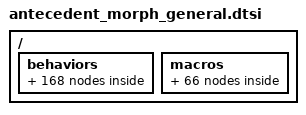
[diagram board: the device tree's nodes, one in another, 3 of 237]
// General schema version v2.9
// Automatically generated by Antecedent Morph Configurator

/ {
    behaviors {
        // Mod-Morphs
        // Base layer
        // NE
        amgnneagm: amgnneagm {
            compatible = "zmk,behavior-mod-morph";
            #binding-cells = <0>;
            bindings = <&amgnnea>, <&amgnneg>;
            mods = <(MOD_LGUI)>;
        };
        amgnnecagm: amgnnecagm {
            compatible = "zmk,behavior-mod-morph";
            #binding-cells = <0>;
            bindings = <&amgnnec>, <&amgnneagm>;
            mods = <(MOD_LALT|MOD_LGUI)>;
        };
        amgnnem: amgnnem {
            compatible = "zmk,behavior-mod-morph";
            #binding-cells = <0>;
            bindings = <&amgnne>, <&amgnnecagm>;
            mods = <(MOD_LCTL|MOD_LALT|MOD_LGUI)>;
        };
        // E
        amgneagm: amgneagm {
            compatible = "zmk,behavior-mod-morph";
            #binding-cells = <0>;
            bindings = <&amgnea>, <&amgneg>;
            mods = <(MOD_LGUI)>;
        };
        amgnecagm: amgnecagm {
            compatible = "zmk,behavior-mod-morph";
            #binding-cells = <0>;
            bindings = <&amgnec>, <&amgneagm>;
            mods = <(MOD_LALT|MOD_LGUI)>;
        };
        amgnem: amgnem {
            compatible = "zmk,behavior-mod-morph";
            #binding-cells = <0>;
            bindings = <&amgne>, <&amgnecagm>;
            mods = <(MOD_LCTL|MOD_LALT|MOD_LGUI)>;
        };
        // SE
        amgnseagm: amgnseagm {
            compatible = "zmk,behavior-mod-morph";
            #binding-cells = <0>;
            bindings = <&amgnsea>, <&amgnseg>;
            mods = <(MOD_LGUI)>;
        };
        amgnsecagm: amgnsecagm {
            compatible = "zmk,behavior-mod-morph";
            #binding-cells = <0>;
            bindings = <&amgnsec>, <&amgnseagm>;
            mods = <(MOD_LALT|MOD_LGUI)>;
        };
        amgnsem: amgnsem {
            compatible = "zmk,behavior-mod-morph";
            #binding-cells = <0>;
            bindings = <&amgnse>, <&amgnsecagm>;
            mods = <(MOD_LCTL|MOD_LALT|MOD_LGUI)>;
        };
        // NW
        amgnnwagm: amgnnwagm {
            compatible = "zmk,behavior-mod-morph";
            #binding-cells = <0>;
            bindings = <&amgnnwa>, <&amgnnwg>;
            mods = <(MOD_RGUI)>;
        };
        amgnnwcagm: amgnnwcagm {
            compatible = "zmk,behavior-mod-morph";
            #binding-cells = <0>;
            bindings = <&amgnnwc>, <&amgnnwagm>;
            mods = <(MOD_RALT|MOD_RGUI)>;
        };
        amgnnwm: amgnnwm {
            compatible = "zmk,behavior-mod-morph";
            #binding-cells = <0>;
            bindings = <&amgnnw>, <&amgnnwcagm>;
            mods = <(MOD_RCTL|MOD_RALT|MOD_RGUI)>;
        };
        // W
        amgnwagm: amgnwagm {
            compatible = "zmk,behavior-mod-morph";
            #binding-cells = <0>;
            bindings = <&amgnwa>, <&amgnwg>;
            mods = <(MOD_RGUI)>;
        };
        amgnwcagm: amgnwcagm {
            compatible = "zmk,behavior-mod-morph";
            #binding-cells = <0>;
            bindings = <&amgnwc>, <&amgnwagm>;
            mods = <(MOD_RALT|MOD_RGUI)>;
        };
        amgnwm: amgnwm {
            compatible = "zmk,behavior-mod-morph";
            #binding-cells = <0>;
            bindings = <&amgnw>, <&amgnwcagm>;
            mods = <(MOD_RCTL|MOD_RALT|MOD_RGUI)>;
        };
        // SW
        amgnswagm: amgnswagm {
            compatible = "zmk,behavior-mod-morph";
            #binding-cells = <0>;
            bindings = <&amgnswa>, <&amgnswg>;
            mods = <(MOD_RGUI)>;
        };
        amgnswcagm: amgnswcagm {
            compatible = "zmk,behavior-mod-morph";
            #binding-cells = <0>;
            bindings = <&amgnswc>, <&amgnswagm>;
            mods = <(MOD_RALT|MOD_RGUI)>;
        };
        amgnswm: amgnswm {
            compatible = "zmk,behavior-mod-morph";
            #binding-cells = <0>;
            bindings = <&amgnsw>, <&amgnswcagm>;
            mods = <(MOD_RCTL|MOD_RALT|MOD_RGUI)>;
        };
        // Mouse layer
        // NE
        amgnmosneagm: amgnmosneagm {
            compatible = "zmk,behavior-mod-morph";
            #binding-cells = <0>;
            bindings = <&amgnmosnea>, <&amgnmosneg>;
            mods = <(MOD_LGUI)>;
        };
        amgnmosnecagm: amgnmosnecagm {
            compatible = "zmk,behavior-mod-morph";
            #binding-cells = <0>;
            bindings = <&amgnmosnec>, <&amgnmosneagm>;
            mods = <(MOD_LALT|MOD_LGUI)>;
        };
        amgnmosnem: amgnmosnem {
            compatible = "zmk,behavior-mod-morph";
            #binding-cells = <0>;
            bindings = <&amgnmosne>, <&amgnmosnecagm>;
            mods = <(MOD_LCTL|MOD_LALT|MOD_LGUI)>;
        };
        // E
        amgnmoseagm: amgnmoseagm {
            compatible = "zmk,behavior-mod-morph";
            #binding-cells = <0>;
            bindings = <&amgnmosea>, <&amgnmoseg>;
            mods = <(MOD_LGUI)>;
        };
        amgnmosecagm: amgnmosecagm {
            compatible = "zmk,behavior-mod-morph";
            #binding-cells = <0>;
            bindings = <&amgnmosec>, <&amgnmoseagm>;
            mods = <(MOD_LALT|MOD_LGUI)>;
        };
        amgnmosem: amgnmosem {
            compatible = "zmk,behavior-mod-morph";
            #binding-cells = <0>;
            bindings = <&amgnmose>, <&amgnmosecagm>;
            mods = <(MOD_LCTL|MOD_LALT|MOD_LGUI)>;
        };
        // SE
        amgnmosseagm: amgnmosseagm {
            compatible = "zmk,behavior-mod-morph";
            #binding-cells = <0>;
            bindings = <&amgnmossea>, <&amgnmosseg>;
            mods = <(MOD_LGUI)>;
        };
        amgnmossecagm: amgnmossecagm {
            compatible = "zmk,behavior-mod-morph";
            #binding-cells = <0>;
            bindings = <&amgnmossec>, <&amgnmosseagm>;
            mods = <(MOD_LALT|MOD_LGUI)>;
        };
        amgnmossem: amgnmossem {
            compatible = "zmk,behavior-mod-morph";
            #binding-cells = <0>;
            bindings = <&amgnmosse>, <&amgnmossecagm>;
            mods = <(MOD_LCTL|MOD_LALT|MOD_LGUI)>;
        };
        // Navigation layer
        // NE
        amgnnavneagm: amgnnavneagm {
            compatible = "zmk,behavior-mod-morph";
            #binding-cells = <0>;
            bindings = <&amgnnavnea>, <&amgnnavneg>;
            mods = <(MOD_LGUI)>;
        };
        amgnnavnecagm: amgnnavnecagm {
            compatible = "zmk,behavior-mod-morph";
            #binding-cells = <0>;
            bindings = <&amgnnavnec>, <&amgnnavneagm>;
            mods = <(MOD_LALT|MOD_LGUI)>;
        };
        amgnnavnem: amgnnavnem {
            compatible = "zmk,behavior-mod-morph";
            #binding-cells = <0>;
            bindings = <&amgnnavne>, <&amgnnavnecagm>;
            mods = <(MOD_LCTL|MOD_LALT|MOD_LGUI)>;
        };
        // E
        amgnnaveagm: amgnnaveagm {
            compatible = "zmk,behavior-mod-morph";
            #binding-cells = <0>;
            bindings = <&amgnnavea>, <&amgnnaveg>;
            mods = <(MOD_LGUI)>;
        };
        amgnnavecagm: amgnnavecagm {
            compatible = "zmk,behavior-mod-morph";
            #binding-cells = <0>;
            bindings = <&amgnnavec>, <&amgnnaveagm>;
            mods = <(MOD_LALT|MOD_LGUI)>;
        };
        amgnnavem: amgnnavem {
            compatible = "zmk,behavior-mod-morph";
            #binding-cells = <0>;
            bindings = <&amgnnave>, <&amgnnavecagm>;
            mods = <(MOD_LCTL|MOD_LALT|MOD_LGUI)>;
        };
        // SE
        amgnnavseagm: amgnnavseagm {
            compatible = "zmk,behavior-mod-morph";
            #binding-cells = <0>;
            bindings = <&amgnnavsea>, <&amgnnavseg>;
            mods = <(MOD_LGUI)>;
        };
        amgnnavsecagm: amgnnavsecagm {
            compatible = "zmk,behavior-mod-morph";
            #binding-cells = <0>;
            bindings = <&amgnnavsec>, <&amgnnavseagm>;
            mods = <(MOD_LALT|MOD_LGUI)>;
        };
        amgnnavsem: amgnnavsem {
            compatible = "zmk,behavior-mod-morph";
            #binding-cells = <0>;
            bindings = <&amgnnavse>, <&amgnnavsecagm>;
            mods = <(MOD_LCTL|MOD_LALT|MOD_LGUI)>;
        };
        // Media layer
        // NE
        amgnmedneagm: amgnmedneagm {
            compatible = "zmk,behavior-mod-morph";
            #binding-cells = <0>;
            bindings = <&amgnmednea>, <&amgnmedneg>;
            mods = <(MOD_LGUI)>;
        };
        amgnmednecagm: amgnmednecagm {
            compatible = "zmk,behavior-mod-morph";
            #binding-cells = <0>;
            bindings = <&amgnmednec>, <&amgnmedneagm>;
            mods = <(MOD_LALT|MOD_LGUI)>;
        };
        amgnmednem: amgnmednem {
            compatible = "zmk,behavior-mod-morph";
            #binding-cells = <0>;
            bindings = <&amgnmedne>, <&amgnmednecagm>;
            mods = <(MOD_LCTL|MOD_LALT|MOD_LGUI)>;
        };
        // E
        amgnmedeagm: amgnmedeagm {
            compatible = "zmk,behavior-mod-morph";
            #binding-cells = <0>;
            bindings = <&amgnmedea>, <&amgnmedeg>;
            mods = <(MOD_LGUI)>;
        };
        amgnmedecagm: amgnmedecagm {
            compatible = "zmk,behavior-mod-morph";
            #binding-cells = <0>;
            bindings = <&amgnmedec>, <&amgnmedeagm>;
            mods = <(MOD_LALT|MOD_LGUI)>;
        };
        amgnmedem: amgnmedem {
            compatible = "zmk,behavior-mod-morph";
            #binding-cells = <0>;
            bindings = <&amgnmede>, <&amgnmedecagm>;
            mods = <(MOD_LCTL|MOD_LALT|MOD_LGUI)>;
        };
        // SE
        amgnmedseagm: amgnmedseagm {
            compatible = "zmk,behavior-mod-morph";
            #binding-cells = <0>;
            bindings = <&amgnmedsea>, <&amgnmedseg>;
            mods = <(MOD_LGUI)>;
        };
        amgnmedsecagm: amgnmedsecagm {
            compatible = "zmk,behavior-mod-morph";
            #binding-cells = <0>;
            bindings = <&amgnmedsec>, <&amgnmedseagm>;
            mods = <(MOD_LALT|MOD_LGUI)>;
        };
        amgnmedsem: amgnmedsem {
            compatible = "zmk,behavior-mod-morph";
            #binding-cells = <0>;
            bindings = <&amgnmedse>, <&amgnmedsecagm>;
            mods = <(MOD_LCTL|MOD_LALT|MOD_LGUI)>;
        };
        // Symbol layer
        // NW
        amgnsymnwagm: amgnsymnwagm {
            compatible = "zmk,behavior-mod-morph";
            #binding-cells = <0>;
            bindings = <&amgnsymnwa>, <&amgnsymnwg>;
            mods = <(MOD_RGUI)>;
        };
        amgnsymnwcagm: amgnsymnwcagm {
            compatible = "zmk,behavior-mod-morph";
            #binding-cells = <0>;
            bindings = <&amgnsymnwc>, <&amgnsymnwagm>;
            mods = <(MOD_RALT|MOD_RGUI)>;
        };
        amgnsymnwm: amgnsymnwm {
            compatible = "zmk,behavior-mod-morph";
            #binding-cells = <0>;
            bindings = <&amgnsymnw>, <&amgnsymnwcagm>;
            mods = <(MOD_RCTL|MOD_RALT|MOD_RGUI)>;
        };
        // W
        amgnsymwagm: amgnsymwagm {
            compatible = "zmk,behavior-mod-morph";
            #binding-cells = <0>;
            bindings = <&amgnsymwa>, <&amgnsymwg>;
            mods = <(MOD_RGUI)>;
        };
        amgnsymwcagm: amgnsymwcagm {
            compatible = "zmk,behavior-mod-morph";
            #binding-cells = <0>;
            bindings = <&amgnsymwc>, <&amgnsymwagm>;
            mods = <(MOD_RALT|MOD_RGUI)>;
        };
        amgnsymwm: amgnsymwm {
            compatible = "zmk,behavior-mod-morph";
            #binding-cells = <0>;
            bindings = <&amgnsymw>, <&amgnsymwcagm>;
            mods = <(MOD_RCTL|MOD_RALT|MOD_RGUI)>;
        };
        // SW
        amgnsymswagm: amgnsymswagm {
            compatible = "zmk,behavior-mod-morph";
            #binding-cells = <0>;
            bindings = <&amgnsymswa>, <&amgnsymswg>;
            mods = <(MOD_RGUI)>;
        };
        amgnsymswcagm: amgnsymswcagm {
            compatible = "zmk,behavior-mod-morph";
            #binding-cells = <0>;
            bindings = <&amgnsymswc>, <&amgnsymswagm>;
            mods = <(MOD_RALT|MOD_RGUI)>;
        };
        amgnsymswm: amgnsymswm {
            compatible = "zmk,behavior-mod-morph";
            #binding-cells = <0>;
            bindings = <&amgnsymsw>, <&amgnsymswcagm>;
            mods = <(MOD_RCTL|MOD_RALT|MOD_RGUI)>;
        };
        // Number layer
        // NW
        amgnnumnwagm: amgnnumnwagm {
            compatible = "zmk,behavior-mod-morph";
            #binding-cells = <0>;
            bindings = <&amgnnumnwa>, <&amgnnumnwg>;
            mods = <(MOD_RGUI)>;
        };
        amgnnumnwcagm: amgnnumnwcagm {
            compatible = "zmk,behavior-mod-morph";
            #binding-cells = <0>;
            bindings = <&amgnnumnwc>, <&amgnnumnwagm>;
            mods = <(MOD_RALT|MOD_RGUI)>;
        };
        amgnnumnwm: amgnnumnwm {
            compatible = "zmk,behavior-mod-morph";
            #binding-cells = <0>;
            bindings = <&amgnnumnw>, <&amgnnumnwcagm>;
            mods = <(MOD_RCTL|MOD_RALT|MOD_RGUI)>;
        };
        // W
        amgnnumwagm: amgnnumwagm {
            compatible = "zmk,behavior-mod-morph";
            #binding-cells = <0>;
            bindings = <&amgnnumwa>, <&amgnnumwg>;
            mods = <(MOD_RGUI)>;
        };
        amgnnumwcagm: amgnnumwcagm {
            compatible = "zmk,behavior-mod-morph";
            #binding-cells = <0>;
            bindings = <&amgnnumwc>, <&amgnnumwagm>;
            mods = <(MOD_RALT|MOD_RGUI)>;
        };
        amgnnumwm: amgnnumwm {
            compatible = "zmk,behavior-mod-morph";
            #binding-cells = <0>;
            bindings = <&amgnnumw>, <&amgnnumwcagm>;
            mods = <(MOD_RCTL|MOD_RALT|MOD_RGUI)>;
        };
        // SW
        amgnnumswagm: amgnnumswagm {
            compatible = "zmk,behavior-mod-morph";
            #binding-cells = <0>;
            bindings = <&amgnnumswa>, <&amgnnumswg>;
            mods = <(MOD_RGUI)>;
        };
        amgnnumswcagm: amgnnumswcagm {
            compatible = "zmk,behavior-mod-morph";
            #binding-cells = <0>;
            bindings = <&amgnnumswc>, <&amgnnumswagm>;
            mods = <(MOD_RALT|MOD_RGUI)>;
        };
        amgnnumswm: amgnnumswm {
            compatible = "zmk,behavior-mod-morph";
            #binding-cells = <0>;
            bindings = <&amgnnumsw>, <&amgnnumswcagm>;
            mods = <(MOD_RCTL|MOD_RALT|MOD_RGUI)>;
        };
        // Function layer
        // NW
        amgnfunnwagm: amgnfunnwagm {
            compatible = "zmk,behavior-mod-morph";
            #binding-cells = <0>;
            bindings = <&amgnfunnwa>, <&amgnfunnwg>;
            mods = <(MOD_RGUI)>;
        };
        amgnfunnwcagm: amgnfunnwcagm {
            compatible = "zmk,behavior-mod-morph";
            #binding-cells = <0>;
            bindings = <&amgnfunnwc>, <&amgnfunnwagm>;
            mods = <(MOD_RALT|MOD_RGUI)>;
        };
        amgnfunnwm: amgnfunnwm {
            compatible = "zmk,behavior-mod-morph";
            #binding-cells = <0>;
            bindings = <&amgnfunnw>, <&amgnfunnwcagm>;
            mods = <(MOD_RCTL|MOD_RALT|MOD_RGUI)>;
        };
        // W
        amgnfunwagm: amgnfunwagm {
            compatible = "zmk,behavior-mod-morph";
            #binding-cells = <0>;
            bindings = <&amgnfunwa>, <&amgnfunwg>;
            mods = <(MOD_RGUI)>;
        };
        amgnfunwcagm: amgnfunwcagm {
            compatible = "zmk,behavior-mod-morph";
            #binding-cells = <0>;
            bindings = <&amgnfunwc>, <&amgnfunwagm>;
            mods = <(MOD_RALT|MOD_RGUI)>;
        };
        amgnfunwm: amgnfunwm {
            compatible = "zmk,behavior-mod-morph";
            #binding-cells = <0>;
            bindings = <&amgnfunw>, <&amgnfunwcagm>;
            mods = <(MOD_RCTL|MOD_RALT|MOD_RGUI)>;
        };
        // SW
        amgnfunswagm: amgnfunswagm {
            compatible = "zmk,behavior-mod-morph";
            #binding-cells = <0>;
            bindings = <&amgnfunswa>, <&amgnfunswg>;
            mods = <(MOD_RGUI)>;
        };
        amgnfunswcagm: amgnfunswcagm {
            compatible = "zmk,behavior-mod-morph";
            #binding-cells = <0>;
            bindings = <&amgnfunswc>, <&amgnfunswagm>;
            mods = <(MOD_RALT|MOD_RGUI)>;
        };
        amgnfunswm: amgnfunswm {
            compatible = "zmk,behavior-mod-morph";
            #binding-cells = <0>;
            bindings = <&amgnfunsw>, <&amgnfunswcagm>;
            mods = <(MOD_RCTL|MOD_RALT|MOD_RGUI)>;
        };
        // Antecedent Morphs
        amgnne: am_gn_ne {
            compatible = "zmk,behavior-antecedent-morph";
            label = "AM_GN_NE";
            #binding-cells = <0>;
            defaults = <&none>;
            bindings = <&amgn_break>, <&amgn_case>, <&amgn_done>, <&amgn_esac>, <&amgn_for>, <&amgn_ping>, <&amgn_sysctl>, <&amgn_trace>, <&amgn_while>, <&amgn_12>, <&amgn_21>, <&kp EQUAL>, <&amgn_prokofyevme>, <&amgn__e>, <&amgn_do>;
            antecedents = <B C D E F P S T W N1 N2 EXCL AT LBKT SEMI>;
            max-delay-ms = <U_ANTMORPH_DELAY>;
        };
        amgnnec: am_gn_ne_c {
            compatible = "zmk,behavior-antecedent-morph";
            label = "AM_GN_NE_C";
            #binding-cells = <0>;
            defaults = <&none>;
            bindings = <&none>;
            antecedents = <0x070100>;
            max-delay-ms = <U_ANTMORPH_DELAY>;
        };
        amgnnea: am_gn_ne_a {
            compatible = "zmk,behavior-antecedent-morph";
            label = "AM_GN_NE_A";
            #binding-cells = <0>;
            defaults = <&none>;
            bindings = <&none>;
            antecedents = <0x070100>;
            max-delay-ms = <U_ANTMORPH_DELAY>;
        };
        amgnneg: am_gn_ne_g {
            compatible = "zmk,behavior-antecedent-morph";
            label = "AM_GN_NE_G";
            #binding-cells = <0>;
            defaults = <&none>;
            bindings = <&none>;
            antecedents = <0x070100>;
            max-delay-ms = <U_ANTMORPH_DELAY>;
        };
        amgne: am_gn_e {
            compatible = "zmk,behavior-antecedent-morph";
            label = "AM_GN_E";
            #binding-cells = <0>;
            defaults = <&none>;
            bindings = <&amgn_chmod>, <&amgn_dictionary>, <&amgn_echo>, <&amgn_grep>, <&amgn_netcat>, <&amgn_proostas>, <&amgn_resolvectl>, <&amgn_sudo>, <&amgn_tmux>, <&amgn_vim>, <&amgn_monday>, <&amgn_tuesday>, <&amgn_wednesday>, <&amgn_thursday>, <&amgn_friday>, <&amgn_saturday>, <&amgn_sunday>, <&amgn_yandexru>, <&amgn_binsh>, <&amgn__>, <&kp SEMI>, <&amgn_then>;
            antecedents = <C D E G N P R S T V N1 N2 N3 N4 N5 N6 N7 AT HASH LBKT RBKT SEMI>;
            max-delay-ms = <U_ANTMORPH_DELAY>;
        };
        amgnec: am_gn_e_c {
            compatible = "zmk,behavior-antecedent-morph";
            label = "AM_GN_E_C";
            #binding-cells = <0>;
            defaults = <&none>;
            bindings = <&amgn_pronunciation>, <&amgn_usrbinpython>, <&amgn_general_v29>;
            antecedents = <P HASH SPACE>;
            max-delay-ms = <U_ANTMORPH_DELAY>;
        };
        amgnea: am_gn_e_a {
            compatible = "zmk,behavior-antecedent-morph";
            label = "AM_GN_E_A";
            #binding-cells = <0>;
            defaults = <&none>;
            bindings = <&amgn_usrbinenv>;
            antecedents = <HASH>;
            max-delay-ms = <U_ANTMORPH_DELAY>;
        };
        amgneg: am_gn_e_g {
            compatible = "zmk,behavior-antecedent-morph";
            label = "AM_GN_E_G";
            #binding-cells = <0>;
            defaults = <&none>;
            bindings = <&none>;
            antecedents = <0x070100>;
            max-delay-ms = <U_ANTMORPH_DELAY>;
        };
        amgnse: am_gn_se {
            compatible = "zmk,behavior-antecedent-morph";
            label = "AM_GN_SE";
            #binding-cells = <0>;
            defaults = <&none>;
            bindings = <&amgn_chown>, <&amgn_nmap>, <&amgn_systemctl>, <&amgn_gmailcom>, <&amgn__x>;
            antecedents = <C N S AT LBKT>;
            max-delay-ms = <U_ANTMORPH_DELAY>;
        };
        amgnsec: am_gn_se_c {
            compatible = "zmk,behavior-antecedent-morph";
            label = "AM_GN_SE_C";
            #binding-cells = <0>;
            defaults = <&none>;
            bindings = <&none>;
            antecedents = <0x070100>;
            max-delay-ms = <U_ANTMORPH_DELAY>;
        };
        amgnsea: am_gn_se_a {
            compatible = "zmk,behavior-antecedent-morph";
            label = "AM_GN_SE_A";
            #binding-cells = <0>;
            defaults = <&none>;
            bindings = <&none>;
            antecedents = <0x070100>;
            max-delay-ms = <U_ANTMORPH_DELAY>;
        };
        amgnseg: am_gn_se_g {
            compatible = "zmk,behavior-antecedent-morph";
            label = "AM_GN_SE_G";
            #binding-cells = <0>;
            defaults = <&none>;
            bindings = <&none>;
            antecedents = <0x070100>;
            max-delay-ms = <U_ANTMORPH_DELAY>;
        };
        amgnnw: am_gn_nw {
            compatible = "zmk,behavior-antecedent-morph";
            label = "AM_GN_NW";
            #binding-cells = <0>;
            defaults = <&none>;
            bindings = <&amgn_elif>, <&amgn_host>, <&amgn_nslookup>, <&amgn__z>, <&kp MINUS>, <&kp MINUS>;
            antecedents = <E H N LBKT MINUS SPACE>;
            max-delay-ms = <U_ANTMORPH_DELAY>;
        };
        amgnnwc: am_gn_nw_c {
            compatible = "zmk,behavior-antecedent-morph";
            label = "AM_GN_NW_C";
            #binding-cells = <0>;
            defaults = <&none>;
            bindings = <&amgn_elif1>, <&amgn__n>;
            antecedents = <E LBKT>;
            max-delay-ms = <U_ANTMORPH_DELAY>;
        };
        amgnnwa: am_gn_nw_a {
            compatible = "zmk,behavior-antecedent-morph";
            label = "AM_GN_NW_A";
            #binding-cells = <0>;
            defaults = <&none>;
            bindings = <&none>;
            antecedents = <0x070100>;
            max-delay-ms = <U_ANTMORPH_DELAY>;
        };
        amgnnwg: am_gn_nw_g {
            compatible = "zmk,behavior-antecedent-morph";
            label = "AM_GN_NW_G";
            #binding-cells = <0>;
            defaults = <&none>;
            bindings = <&none>;
            antecedents = <0x070100>;
            max-delay-ms = <U_ANTMORPH_DELAY>;
        };
        amgnw: am_gn_w {
            compatible = "zmk,behavior-antecedent-morph";
            label = "AM_GN_W";
            #binding-cells = <0>;
            defaults = <&none>;
            bindings = <&amgn_curl>, <&amgn_else>, <&amgn_https>, <&amgn_if>, <&amgn_journalctl>, <&amgn_lsof>, <&amgn_meaning>, <&amgn_nmcli>, <&amgn_html>, <&kp EQUAL>, <&kp EQUAL>;
            antecedents = <C E H I J L M N DOT EQUAL SPACE>;
            max-delay-ms = <U_ANTMORPH_DELAY>;
        };
        amgnwc: am_gn_w_c {
            compatible = "zmk,behavior-antecedent-morph";
            label = "AM_GN_W_C";
            #binding-cells = <0>;
            defaults = <&none>;
            bindings = <&amgn_http>, <&amgn_if1>, <&amgn_m>;
            antecedents = <H I SPACE>;
            max-delay-ms = <U_ANTMORPH_DELAY>;
        };
        amgnwa: am_gn_w_a {
            compatible = "zmk,behavior-antecedent-morph";
            label = "AM_GN_W_A";
            #binding-cells = <0>;
            defaults = <&none>;
            bindings = <&amgn_m1>;
            antecedents = <SPACE>;
            max-delay-ms = <U_ANTMORPH_DELAY>;
        };
        amgnwg: am_gn_w_g {
            compatible = "zmk,behavior-antecedent-morph";
            label = "AM_GN_W_G";
            #binding-cells = <0>;
            defaults = <&none>;
            bindings = <&none>;
            antecedents = <0x070100>;
            max-delay-ms = <U_ANTMORPH_DELAY>;
        };
        amgnsw: am_gn_sw {
            compatible = "zmk,behavior-antecedent-morph";
            label = "AM_GN_SW";
            #binding-cells = <0>;
            defaults = <&none>;
            bindings = <&amgn_exit>, <&amgn_mount>, <&amgn_netstat>;
            antecedents = <E M N>;
            max-delay-ms = <U_ANTMORPH_DELAY>;
        };
        amgnswc: am_gn_sw_c {
            compatible = "zmk,behavior-antecedent-morph";
            label = "AM_GN_SW_C";
            #binding-cells = <0>;
            defaults = <&none>;
            bindings = <&none>;
            antecedents = <0x070100>;
            max-delay-ms = <U_ANTMORPH_DELAY>;
        };
        amgnswa: am_gn_sw_a {
            compatible = "zmk,behavior-antecedent-morph";
            label = "AM_GN_SW_A";
            #binding-cells = <0>;
            defaults = <&none>;
            bindings = <&none>;
            antecedents = <0x070100>;
            max-delay-ms = <U_ANTMORPH_DELAY>;
        };
        amgnswg: am_gn_sw_g {
            compatible = "zmk,behavior-antecedent-morph";
            label = "AM_GN_SW_G";
            #binding-cells = <0>;
            defaults = <&none>;
            bindings = <&none>;
            antecedents = <0x070100>;
            max-delay-ms = <U_ANTMORPH_DELAY>;
        };
        amgnmosne: am_gn_mos_ne {
            compatible = "zmk,behavior-antecedent-morph";
            label = "AM_GN_MOS_NE";
            #binding-cells = <0>;
            defaults = <&none>;
            bindings = <&none>;
            antecedents = <0x070100>;
            max-delay-ms = <U_ANTMORPH_DELAY>;
        };
        amgnmosnec: am_gn_mos_ne_c {
            compatible = "zmk,behavior-antecedent-morph";
            label = "AM_GN_MOS_NE_C";
            #binding-cells = <0>;
            defaults = <&none>;
            bindings = <&none>;
            antecedents = <0x070100>;
            max-delay-ms = <U_ANTMORPH_DELAY>;
        };
        amgnmosnea: am_gn_mos_ne_a {
            compatible = "zmk,behavior-antecedent-morph";
            label = "AM_GN_MOS_NE_A";
            #binding-cells = <0>;
            defaults = <&none>;
            bindings = <&none>;
            antecedents = <0x070100>;
            max-delay-ms = <U_ANTMORPH_DELAY>;
        };
        amgnmosneg: am_gn_mos_ne_g {
            compatible = "zmk,behavior-antecedent-morph";
            label = "AM_GN_MOS_NE_G";
            #binding-cells = <0>;
            defaults = <&none>;
            bindings = <&none>;
            antecedents = <0x070100>;
            max-delay-ms = <U_ANTMORPH_DELAY>;
        };
        amgnmose: am_gn_mos_e {
            compatible = "zmk,behavior-antecedent-morph";
            label = "AM_GN_MOS_E";
            #binding-cells = <0>;
            defaults = <&none>;
            bindings = <&none>;
            antecedents = <0x070100>;
            max-delay-ms = <U_ANTMORPH_DELAY>;
        };
        amgnmosec: am_gn_mos_e_c {
            compatible = "zmk,behavior-antecedent-morph";
            label = "AM_GN_MOS_E_C";
            #binding-cells = <0>;
            defaults = <&none>;
            bindings = <&none>;
            antecedents = <0x070100>;
            max-delay-ms = <U_ANTMORPH_DELAY>;
        };
        amgnmosea: am_gn_mos_e_a {
            compatible = "zmk,behavior-antecedent-morph";
            label = "AM_GN_MOS_E_A";
            #binding-cells = <0>;
            defaults = <&none>;
            bindings = <&none>;
            antecedents = <0x070100>;
            max-delay-ms = <U_ANTMORPH_DELAY>;
        };
        amgnmoseg: am_gn_mos_e_g {
            compatible = "zmk,behavior-antecedent-morph";
            label = "AM_GN_MOS_E_G";
            #binding-cells = <0>;
            defaults = <&none>;
            bindings = <&none>;
            antecedents = <0x070100>;
            max-delay-ms = <U_ANTMORPH_DELAY>;
        };
        amgnmosse: am_gn_mos_se {
            compatible = "zmk,behavior-antecedent-morph";
            label = "AM_GN_MOS_SE";
            #binding-cells = <0>;
            defaults = <&none>;
            bindings = <&none>;
            antecedents = <0x070100>;
            max-delay-ms = <U_ANTMORPH_DELAY>;
        };
        amgnmossec: am_gn_mos_se_c {
            compatible = "zmk,behavior-antecedent-morph";
            label = "AM_GN_MOS_SE_C";
            #binding-cells = <0>;
            defaults = <&none>;
            bindings = <&none>;
            antecedents = <0x070100>;
            max-delay-ms = <U_ANTMORPH_DELAY>;
        };
        amgnmossea: am_gn_mos_se_a {
            compatible = "zmk,behavior-antecedent-morph";
            label = "AM_GN_MOS_SE_A";
            #binding-cells = <0>;
            defaults = <&none>;
            bindings = <&none>;
            antecedents = <0x070100>;
            max-delay-ms = <U_ANTMORPH_DELAY>;
        };
        amgnmosseg: am_gn_mos_se_g {
            compatible = "zmk,behavior-antecedent-morph";
            label = "AM_GN_MOS_SE_G";
            #binding-cells = <0>;
            defaults = <&none>;
            bindings = <&none>;
            antecedents = <0x070100>;
            max-delay-ms = <U_ANTMORPH_DELAY>;
        };
        amgnnavne: am_gn_nav_ne {
            compatible = "zmk,behavior-antecedent-morph";
            label = "AM_GN_NAV_NE";
            #binding-cells = <0>;
            defaults = <&none>;
            bindings = <&none>;
            antecedents = <0x070100>;
            max-delay-ms = <U_ANTMORPH_DELAY>;
        };
        amgnnavnec: am_gn_nav_ne_c {
            compatible = "zmk,behavior-antecedent-morph";
            label = "AM_GN_NAV_NE_C";
            #binding-cells = <0>;
            defaults = <&none>;
            bindings = <&none>;
            antecedents = <0x070100>;
            max-delay-ms = <U_ANTMORPH_DELAY>;
        };
        amgnnavnea: am_gn_nav_ne_a {
            compatible = "zmk,behavior-antecedent-morph";
            label = "AM_GN_NAV_NE_A";
            #binding-cells = <0>;
            defaults = <&none>;
            bindings = <&none>;
            antecedents = <0x070100>;
            max-delay-ms = <U_ANTMORPH_DELAY>;
        };
        amgnnavneg: am_gn_nav_ne_g {
            compatible = "zmk,behavior-antecedent-morph";
            label = "AM_GN_NAV_NE_G";
            #binding-cells = <0>;
            defaults = <&none>;
            bindings = <&none>;
            antecedents = <0x070100>;
            max-delay-ms = <U_ANTMORPH_DELAY>;
        };
        amgnnave: am_gn_nav_e {
            compatible = "zmk,behavior-antecedent-morph";
            label = "AM_GN_NAV_E";
            #binding-cells = <0>;
            defaults = <&none>;
            bindings = <&none>;
            antecedents = <0x070100>;
            max-delay-ms = <U_ANTMORPH_DELAY>;
        };
        amgnnavec: am_gn_nav_e_c {
            compatible = "zmk,behavior-antecedent-morph";
            label = "AM_GN_NAV_E_C";
            #binding-cells = <0>;
            defaults = <&none>;
            bindings = <&none>;
            antecedents = <0x070100>;
            max-delay-ms = <U_ANTMORPH_DELAY>;
        };
        amgnnavea: am_gn_nav_e_a {
            compatible = "zmk,behavior-antecedent-morph";
            label = "AM_GN_NAV_E_A";
            #binding-cells = <0>;
            defaults = <&none>;
            bindings = <&none>;
            antecedents = <0x070100>;
            max-delay-ms = <U_ANTMORPH_DELAY>;
        };
        amgnnaveg: am_gn_nav_e_g {
            compatible = "zmk,behavior-antecedent-morph";
            label = "AM_GN_NAV_E_G";
            #binding-cells = <0>;
            defaults = <&none>;
            bindings = <&none>;
            antecedents = <0x070100>;
            max-delay-ms = <U_ANTMORPH_DELAY>;
        };
        amgnnavse: am_gn_nav_se {
            compatible = "zmk,behavior-antecedent-morph";
            label = "AM_GN_NAV_SE";
            #binding-cells = <0>;
            defaults = <&none>;
            bindings = <&none>;
            antecedents = <0x070100>;
            max-delay-ms = <U_ANTMORPH_DELAY>;
        };
        amgnnavsec: am_gn_nav_se_c {
            compatible = "zmk,behavior-antecedent-morph";
            label = "AM_GN_NAV_SE_C";
            #binding-cells = <0>;
            defaults = <&none>;
            bindings = <&none>;
            antecedents = <0x070100>;
            max-delay-ms = <U_ANTMORPH_DELAY>;
        };
        amgnnavsea: am_gn_nav_se_a {
            compatible = "zmk,behavior-antecedent-morph";
            label = "AM_GN_NAV_SE_A";
            #binding-cells = <0>;
            defaults = <&none>;
            bindings = <&none>;
            antecedents = <0x070100>;
            max-delay-ms = <U_ANTMORPH_DELAY>;
        };
        amgnnavseg: am_gn_nav_se_g {
            compatible = "zmk,behavior-antecedent-morph";
            label = "AM_GN_NAV_SE_G";
            #binding-cells = <0>;
            defaults = <&none>;
            bindings = <&none>;
            antecedents = <0x070100>;
            max-delay-ms = <U_ANTMORPH_DELAY>;
        };
        amgnmedne: am_gn_med_ne {
            compatible = "zmk,behavior-antecedent-morph";
            label = "AM_GN_MED_NE";
            #binding-cells = <0>;
            defaults = <&none>;
            bindings = <&none>;
            antecedents = <0x070100>;
            max-delay-ms = <U_ANTMORPH_DELAY>;
        };
        amgnmednec: am_gn_med_ne_c {
            compatible = "zmk,behavior-antecedent-morph";
            label = "AM_GN_MED_NE_C";
            #binding-cells = <0>;
            defaults = <&none>;
            bindings = <&none>;
            antecedents = <0x070100>;
            max-delay-ms = <U_ANTMORPH_DELAY>;
        };
        amgnmednea: am_gn_med_ne_a {
            compatible = "zmk,behavior-antecedent-morph";
            label = "AM_GN_MED_NE_A";
            #binding-cells = <0>;
            defaults = <&none>;
            bindings = <&none>;
            antecedents = <0x070100>;
            max-delay-ms = <U_ANTMORPH_DELAY>;
        };
        amgnmedneg: am_gn_med_ne_g {
            compatible = "zmk,behavior-antecedent-morph";
            label = "AM_GN_MED_NE_G";
            #binding-cells = <0>;
            defaults = <&none>;
            bindings = <&none>;
            antecedents = <0x070100>;
            max-delay-ms = <U_ANTMORPH_DELAY>;
        };
        amgnmede: am_gn_med_e {
            compatible = "zmk,behavior-antecedent-morph";
            label = "AM_GN_MED_E";
            #binding-cells = <0>;
            defaults = <&none>;
            bindings = <&none>;
            antecedents = <0x070100>;
            max-delay-ms = <U_ANTMORPH_DELAY>;
        };
        amgnmedec: am_gn_med_e_c {
            compatible = "zmk,behavior-antecedent-morph";
            label = "AM_GN_MED_E_C";
            #binding-cells = <0>;
            defaults = <&none>;
            bindings = <&none>;
            antecedents = <0x070100>;
            max-delay-ms = <U_ANTMORPH_DELAY>;
        };
        amgnmedea: am_gn_med_e_a {
            compatible = "zmk,behavior-antecedent-morph";
            label = "AM_GN_MED_E_A";
            #binding-cells = <0>;
            defaults = <&none>;
            bindings = <&none>;
            antecedents = <0x070100>;
            max-delay-ms = <U_ANTMORPH_DELAY>;
        };
        amgnmedeg: am_gn_med_e_g {
            compatible = "zmk,behavior-antecedent-morph";
            label = "AM_GN_MED_E_G";
            #binding-cells = <0>;
            defaults = <&none>;
            bindings = <&none>;
            antecedents = <0x070100>;
            max-delay-ms = <U_ANTMORPH_DELAY>;
        };
        amgnmedse: am_gn_med_se {
            compatible = "zmk,behavior-antecedent-morph";
            label = "AM_GN_MED_SE";
            #binding-cells = <0>;
            defaults = <&none>;
            bindings = <&none>;
            antecedents = <0x070100>;
            max-delay-ms = <U_ANTMORPH_DELAY>;
        };
        amgnmedsec: am_gn_med_se_c {
            compatible = "zmk,behavior-antecedent-morph";
            label = "AM_GN_MED_SE_C";
            #binding-cells = <0>;
            defaults = <&none>;
            bindings = <&none>;
            antecedents = <0x070100>;
            max-delay-ms = <U_ANTMORPH_DELAY>;
        };
        amgnmedsea: am_gn_med_se_a {
            compatible = "zmk,behavior-antecedent-morph";
            label = "AM_GN_MED_SE_A";
            #binding-cells = <0>;
            defaults = <&none>;
            bindings = <&none>;
            antecedents = <0x070100>;
            max-delay-ms = <U_ANTMORPH_DELAY>;
        };
        amgnmedseg: am_gn_med_se_g {
            compatible = "zmk,behavior-antecedent-morph";
            label = "AM_GN_MED_SE_G";
            #binding-cells = <0>;
            defaults = <&none>;
            bindings = <&none>;
            antecedents = <0x070100>;
            max-delay-ms = <U_ANTMORPH_DELAY>;
        };
        amgnfunnw: am_gn_fun_nw {
            compatible = "zmk,behavior-antecedent-morph";
            label = "AM_GN_FUN_NW";
            #binding-cells = <0>;
            defaults = <&none>;
            bindings = <&none>;
            antecedents = <0x070100>;
            max-delay-ms = <U_ANTMORPH_DELAY>;
        };
        amgnfunnwc: am_gn_fun_nw_c {
            compatible = "zmk,behavior-antecedent-morph";
            label = "AM_GN_FUN_NW_C";
            #binding-cells = <0>;
            defaults = <&none>;
            bindings = <&none>;
            antecedents = <0x070100>;
            max-delay-ms = <U_ANTMORPH_DELAY>;
        };
        amgnfunnwa: am_gn_fun_nw_a {
            compatible = "zmk,behavior-antecedent-morph";
            label = "AM_GN_FUN_NW_A";
            #binding-cells = <0>;
            defaults = <&none>;
            bindings = <&none>;
            antecedents = <0x070100>;
            max-delay-ms = <U_ANTMORPH_DELAY>;
        };
        amgnfunnwg: am_gn_fun_nw_g {
            compatible = "zmk,behavior-antecedent-morph";
            label = "AM_GN_FUN_NW_G";
            #binding-cells = <0>;
            defaults = <&none>;
            bindings = <&none>;
            antecedents = <0x070100>;
            max-delay-ms = <U_ANTMORPH_DELAY>;
        };
        amgnfunw: am_gn_fun_w {
            compatible = "zmk,behavior-antecedent-morph";
            label = "AM_GN_FUN_W";
            #binding-cells = <0>;
            defaults = <&none>;
            bindings = <&none>;
            antecedents = <0x070100>;
            max-delay-ms = <U_ANTMORPH_DELAY>;
        };
        amgnfunwc: am_gn_fun_w_c {
            compatible = "zmk,behavior-antecedent-morph";
            label = "AM_GN_FUN_W_C";
            #binding-cells = <0>;
            defaults = <&none>;
            bindings = <&none>;
            antecedents = <0x070100>;
            max-delay-ms = <U_ANTMORPH_DELAY>;
        };
        amgnfunwa: am_gn_fun_w_a {
            compatible = "zmk,behavior-antecedent-morph";
            label = "AM_GN_FUN_W_A";
            #binding-cells = <0>;
            defaults = <&none>;
            bindings = <&none>;
            antecedents = <0x070100>;
            max-delay-ms = <U_ANTMORPH_DELAY>;
        };
        amgnfunwg: am_gn_fun_w_g {
            compatible = "zmk,behavior-antecedent-morph";
            label = "AM_GN_FUN_W_G";
            #binding-cells = <0>;
            defaults = <&none>;
            bindings = <&none>;
            antecedents = <0x070100>;
            max-delay-ms = <U_ANTMORPH_DELAY>;
        };
        amgnfunsw: am_gn_fun_sw {
            compatible = "zmk,behavior-antecedent-morph";
            label = "AM_GN_FUN_SW";
            #binding-cells = <0>;
            defaults = <&none>;
            bindings = <&none>;
            antecedents = <0x070100>;
            max-delay-ms = <U_ANTMORPH_DELAY>;
        };
        amgnfunswc: am_gn_fun_sw_c {
            compatible = "zmk,behavior-antecedent-morph";
            label = "AM_GN_FUN_SW_C";
            #binding-cells = <0>;
            defaults = <&none>;
            bindings = <&none>;
            antecedents = <0x070100>;
            max-delay-ms = <U_ANTMORPH_DELAY>;
        };
        amgnfunswa: am_gn_fun_sw_a {
            compatible = "zmk,behavior-antecedent-morph";
            label = "AM_GN_FUN_SW_A";
            #binding-cells = <0>;
            defaults = <&none>;
            bindings = <&none>;
            antecedents = <0x070100>;
            max-delay-ms = <U_ANTMORPH_DELAY>;
        };
        amgnfunswg: am_gn_fun_sw_g {
            compatible = "zmk,behavior-antecedent-morph";
            label = "AM_GN_FUN_SW_G";
            #binding-cells = <0>;
            defaults = <&none>;
            bindings = <&none>;
            antecedents = <0x070100>;
            max-delay-ms = <U_ANTMORPH_DELAY>;
        };
        amgnnumnw: am_gn_num_nw {
            compatible = "zmk,behavior-antecedent-morph";
            label = "AM_GN_NUM_NW";
            #binding-cells = <0>;
            defaults = <&none>;
            bindings = <&kp APOS>, <&kp APOS>, <&kp APOS>, <&kp APOS>, <&kp APOS>, <&kp APOS>, <&kp APOS>, <&kp APOS>, <&kp APOS>, <&kp APOS>, <&kp LPAR>, <&kp RPAR>;
            antecedents = <N0 N1 N2 N3 N4 N5 N6 N7 N8 N9 LBKT RBKT>;
            max-delay-ms = <U_ANTMORPH_DELAY>;
        };
        amgnnumnwc: am_gn_num_nw_c {
            compatible = "zmk,behavior-antecedent-morph";
            label = "AM_GN_NUM_NW_C";
            #binding-cells = <0>;
            defaults = <&none>;
            bindings = <&none>;
            antecedents = <0x070100>;
            max-delay-ms = <U_ANTMORPH_DELAY>;
        };
        amgnnumnwa: am_gn_num_nw_a {
            compatible = "zmk,behavior-antecedent-morph";
            label = "AM_GN_NUM_NW_A";
            #binding-cells = <0>;
            defaults = <&none>;
            bindings = <&none>;
            antecedents = <0x070100>;
            max-delay-ms = <U_ANTMORPH_DELAY>;
        };
        amgnnumnwg: am_gn_num_nw_g {
            compatible = "zmk,behavior-antecedent-morph";
            label = "AM_GN_NUM_NW_G";
            #binding-cells = <0>;
            defaults = <&none>;
            bindings = <&none>;
            antecedents = <0x070100>;
            max-delay-ms = <U_ANTMORPH_DELAY>;
        };
        amgnnumw: am_gn_num_w {
            compatible = "zmk,behavior-antecedent-morph";
            label = "AM_GN_NUM_W";
            #binding-cells = <0>;
            defaults = <&none>;
            bindings = <&kp X>;
            antecedents = <N0>;
            max-delay-ms = <U_ANTMORPH_DELAY>;
        };
        amgnnumwc: am_gn_num_w_c {
            compatible = "zmk,behavior-antecedent-morph";
            label = "AM_GN_NUM_W_C";
            #binding-cells = <0>;
            defaults = <&none>;
            bindings = <&none>;
            antecedents = <0x070100>;
            max-delay-ms = <U_ANTMORPH_DELAY>;
        };
        amgnnumwa: am_gn_num_w_a {
            compatible = "zmk,behavior-antecedent-morph";
            label = "AM_GN_NUM_W_A";
            #binding-cells = <0>;
            defaults = <&none>;
            bindings = <&none>;
            antecedents = <0x070100>;
            max-delay-ms = <U_ANTMORPH_DELAY>;
        };
        amgnnumwg: am_gn_num_w_g {
            compatible = "zmk,behavior-antecedent-morph";
            label = "AM_GN_NUM_W_G";
            #binding-cells = <0>;
            defaults = <&none>;
            bindings = <&none>;
            antecedents = <0x070100>;
            max-delay-ms = <U_ANTMORPH_DELAY>;
        };
        amgnnumsw: am_gn_num_sw {
            compatible = "zmk,behavior-antecedent-morph";
            label = "AM_GN_NUM_SW";
            #binding-cells = <0>;
            defaults = <&none>;
            bindings = <&kp B>;
            antecedents = <N0>;
            max-delay-ms = <U_ANTMORPH_DELAY>;
        };
        amgnnumswc: am_gn_num_sw_c {
            compatible = "zmk,behavior-antecedent-morph";
            label = "AM_GN_NUM_SW_C";
            #binding-cells = <0>;
            defaults = <&none>;
            bindings = <&none>;
            antecedents = <0x070100>;
            max-delay-ms = <U_ANTMORPH_DELAY>;
        };
        amgnnumswa: am_gn_num_sw_a {
            compatible = "zmk,behavior-antecedent-morph";
            label = "AM_GN_NUM_SW_A";
            #binding-cells = <0>;
            defaults = <&none>;
            bindings = <&none>;
            antecedents = <0x070100>;
            max-delay-ms = <U_ANTMORPH_DELAY>;
        };
        amgnnumswg: am_gn_num_sw_g {
            compatible = "zmk,behavior-antecedent-morph";
            label = "AM_GN_NUM_SW_G";
            #binding-cells = <0>;
            defaults = <&none>;
            bindings = <&none>;
            antecedents = <0x070100>;
            max-delay-ms = <U_ANTMORPH_DELAY>;
        };
        amgnsymnw: am_gn_sym_nw {
            compatible = "zmk,behavior-antecedent-morph";
            label = "AM_GN_SYM_NW";
            #binding-cells = <0>;
            defaults = <&none>;
            bindings = <&kp LBKT>, <&kp RBKT>, <&kp LBKT>, <&kp RBKT>, <&kp MINUS>;
            antecedents = <LBRC RBRC LPAR RPAR STAR>;
            max-delay-ms = <U_ANTMORPH_DELAY>;
        };
        amgnsymnwc: am_gn_sym_nw_c {
            compatible = "zmk,behavior-antecedent-morph";
            label = "AM_GN_SYM_NW_C";
            #binding-cells = <0>;
            defaults = <&none>;
            bindings = <&none>;
            antecedents = <0x070100>;
            max-delay-ms = <U_ANTMORPH_DELAY>;
        };
        amgnsymnwa: am_gn_sym_nw_a {
            compatible = "zmk,behavior-antecedent-morph";
            label = "AM_GN_SYM_NW_A";
            #binding-cells = <0>;
            defaults = <&none>;
            bindings = <&none>;
            antecedents = <0x070100>;
            max-delay-ms = <U_ANTMORPH_DELAY>;
        };
        amgnsymnwg: am_gn_sym_nw_g {
            compatible = "zmk,behavior-antecedent-morph";
            label = "AM_GN_SYM_NW_G";
            #binding-cells = <0>;
            defaults = <&none>;
            bindings = <&none>;
            antecedents = <0x070100>;
            max-delay-ms = <U_ANTMORPH_DELAY>;
        };
        amgnsymw: am_gn_sym_w {
            compatible = "zmk,behavior-antecedent-morph";
            label = "AM_GN_SYM_W";
            #binding-cells = <0>;
            defaults = <&none>;
            bindings = <&none>;
            antecedents = <0x070100>;
            max-delay-ms = <U_ANTMORPH_DELAY>;
        };
        amgnsymwc: am_gn_sym_w_c {
            compatible = "zmk,behavior-antecedent-morph";
            label = "AM_GN_SYM_W_C";
            #binding-cells = <0>;
            defaults = <&none>;
            bindings = <&none>;
            antecedents = <0x070100>;
            max-delay-ms = <U_ANTMORPH_DELAY>;
        };
        amgnsymwa: am_gn_sym_w_a {
            compatible = "zmk,behavior-antecedent-morph";
            label = "AM_GN_SYM_W_A";
            #binding-cells = <0>;
            defaults = <&none>;
            bindings = <&none>;
            antecedents = <0x070100>;
            max-delay-ms = <U_ANTMORPH_DELAY>;
        };
        amgnsymwg: am_gn_sym_w_g {
            compatible = "zmk,behavior-antecedent-morph";
            label = "AM_GN_SYM_W_G";
            #binding-cells = <0>;
            defaults = <&none>;
            bindings = <&none>;
            antecedents = <0x070100>;
            max-delay-ms = <U_ANTMORPH_DELAY>;
        };
        amgnsymsw: am_gn_sym_sw {
            compatible = "zmk,behavior-antecedent-morph";
            label = "AM_GN_SYM_SW";
            #binding-cells = <0>;
            defaults = <&none>;
            bindings = <&none>;
            antecedents = <0x070100>;
            max-delay-ms = <U_ANTMORPH_DELAY>;
        };
        amgnsymswc: am_gn_sym_sw_c {
            compatible = "zmk,behavior-antecedent-morph";
            label = "AM_GN_SYM_SW_C";
            #binding-cells = <0>;
            defaults = <&none>;
            bindings = <&none>;
            antecedents = <0x070100>;
            max-delay-ms = <U_ANTMORPH_DELAY>;
        };
        amgnsymswa: am_gn_sym_sw_a {
            compatible = "zmk,behavior-antecedent-morph";
            label = "AM_GN_SYM_SW_A";
            #binding-cells = <0>;
            defaults = <&none>;
            bindings = <&none>;
            antecedents = <0x070100>;
            max-delay-ms = <U_ANTMORPH_DELAY>;
        };
        amgnsymswg: am_gn_sym_sw_g {
            compatible = "zmk,behavior-antecedent-morph";
            label = "AM_GN_SYM_SW_G";
            #binding-cells = <0>;
            defaults = <&none>;
            bindings = <&none>;
            antecedents = <0x070100>;
            max-delay-ms = <U_ANTMORPH_DELAY>;
        };
    };
    macros {
        // 'B'
        amgn_break: amgn_break {
            compatible = "zmk,behavior-macro";
            #binding-cells = <0>;
            wait-ms = <U_ANTMORPH_MACRO_WAIT>;
            tap-ms = <U_ANTMORPH_MACRO_TAP>;
            // (b)reak
            bindings = <&macro_tap &kp R &kp E &kp A &kp K>;
        };
        // 'C'
        amgn_case: amgn_case {
            compatible = "zmk,behavior-macro";
            #binding-cells = <0>;
            wait-ms = <U_ANTMORPH_MACRO_WAIT>;
            tap-ms = <U_ANTMORPH_MACRO_TAP>;
            // (c)ase 
            bindings = <&macro_tap &kp A &kp S &kp E &kp SPACE>;
        };
        amgn_chmod: amgn_chmod {
            compatible = "zmk,behavior-macro";
            #binding-cells = <0>;
            wait-ms = <U_ANTMORPH_MACRO_WAIT>;
            tap-ms = <U_ANTMORPH_MACRO_TAP>;
            // (c)hmod 
            bindings = <&macro_tap &kp H &kp M &kp O &kp D &kp SPACE>;
        };
        amgn_chown: amgn_chown {
            compatible = "zmk,behavior-macro";
            #binding-cells = <0>;
            wait-ms = <U_ANTMORPH_MACRO_WAIT>;
            tap-ms = <U_ANTMORPH_MACRO_TAP>;
            // (c)hown 
            bindings = <&macro_tap &kp H &kp O &kp W &kp N &kp SPACE>;
        };
        amgn_curl: amgn_curl {
            compatible = "zmk,behavior-macro";
            #binding-cells = <0>;
            wait-ms = <U_ANTMORPH_MACRO_WAIT>;
            tap-ms = <U_ANTMORPH_MACRO_TAP>;
            // (c)url 
            bindings = <&macro_tap &kp U &kp R &kp L &kp SPACE>;
        };
        // 'D'
        amgn_done: amgn_done {
            compatible = "zmk,behavior-macro";
            #binding-cells = <0>;
            wait-ms = <U_ANTMORPH_MACRO_WAIT>;
            tap-ms = <U_ANTMORPH_MACRO_TAP>;
            // (d)one
            bindings = <&macro_tap &kp O &kp N &kp E>;
        };
        amgn_dictionary: amgn_dictionary {
            compatible = "zmk,behavior-macro";
            #binding-cells = <0>;
            wait-ms = <U_ANTMORPH_MACRO_WAIT>;
            tap-ms = <U_ANTMORPH_MACRO_TAP>;
            // (d)ictionary
            bindings = <&macro_tap &kp I &kp C &kp T &kp I &kp O &kp N &kp A &kp R &kp Y>;
        };
        // 'E'
        amgn_esac: amgn_esac {
            compatible = "zmk,behavior-macro";
            #binding-cells = <0>;
            wait-ms = <U_ANTMORPH_MACRO_WAIT>;
            tap-ms = <U_ANTMORPH_MACRO_TAP>;
            // (e)sac
            bindings = <&macro_tap &kp S &kp A &kp C>;
        };
        amgn_echo: amgn_echo {
            compatible = "zmk,behavior-macro";
            #binding-cells = <0>;
            wait-ms = <U_ANTMORPH_MACRO_WAIT>;
            tap-ms = <U_ANTMORPH_MACRO_TAP>;
            // (e)cho 
            bindings = <&macro_tap &kp C &kp H &kp O &kp SPACE>;
        };
        amgn_elif: amgn_elif {
            compatible = "zmk,behavior-macro";
            #binding-cells = <0>;
            wait-ms = <U_ANTMORPH_MACRO_WAIT>;
            tap-ms = <U_ANTMORPH_MACRO_TAP>;
            // (e)lif 
            bindings = <&macro_tap &kp L &kp I &kp F &kp SPACE>;
        };
        amgn_elif1: amgn_elif1 {
            compatible = "zmk,behavior-macro";
            #binding-cells = <0>;
            wait-ms = <U_ANTMORPH_MACRO_WAIT>;
            tap-ms = <U_ANTMORPH_MACRO_TAP>;
            // (e)lif [ 
            bindings = <&macro_release &kp RCTRL>, <&macro_tap &kp L &kp I &kp F &kp SPACE &kp LBKT &kp SPACE>;
        };
        amgn_else: amgn_else {
            compatible = "zmk,behavior-macro";
            #binding-cells = <0>;
            wait-ms = <U_ANTMORPH_MACRO_WAIT>;
            tap-ms = <U_ANTMORPH_MACRO_TAP>;
            // (e)lse⏎
            bindings = <&macro_tap &kp L &kp S &kp E &kp RET>;
        };
        amgn_exit: amgn_exit {
            compatible = "zmk,behavior-macro";
            #binding-cells = <0>;
            wait-ms = <U_ANTMORPH_MACRO_WAIT>;
            tap-ms = <U_ANTMORPH_MACRO_TAP>;
            // (e)xit 
            bindings = <&macro_tap &kp X &kp I &kp T &kp SPACE>;
        };
        // 'F'
        amgn_for: amgn_for {
            compatible = "zmk,behavior-macro";
            #binding-cells = <0>;
            wait-ms = <U_ANTMORPH_MACRO_WAIT>;
            tap-ms = <U_ANTMORPH_MACRO_TAP>;
            // (f)or 
            bindings = <&macro_tap &kp O &kp R &kp SPACE>;
        };
        // 'G'
        amgn_grep: amgn_grep {
            compatible = "zmk,behavior-macro";
            #binding-cells = <0>;
            wait-ms = <U_ANTMORPH_MACRO_WAIT>;
            tap-ms = <U_ANTMORPH_MACRO_TAP>;
            // (g)rep 
            bindings = <&macro_tap &kp R &kp E &kp P &kp SPACE>;
        };
        // 'H'
        amgn_host: amgn_host {
            compatible = "zmk,behavior-macro";
            #binding-cells = <0>;
            wait-ms = <U_ANTMORPH_MACRO_WAIT>;
            tap-ms = <U_ANTMORPH_MACRO_TAP>;
            // (h)ost 
            bindings = <&macro_tap &kp O &kp S &kp T &kp SPACE>;
        };
        amgn_https: amgn_https {
            compatible = "zmk,behavior-macro";
            #binding-cells = <0>;
            wait-ms = <U_ANTMORPH_MACRO_WAIT>;
            tap-ms = <U_ANTMORPH_MACRO_TAP>;
            // (h)ttps://
            bindings = <&macro_tap &kp T &kp T &kp P &kp S &kp COLON &kp FSLH &kp FSLH>;
        };
        amgn_http: amgn_http {
            compatible = "zmk,behavior-macro";
            #binding-cells = <0>;
            wait-ms = <U_ANTMORPH_MACRO_WAIT>;
            tap-ms = <U_ANTMORPH_MACRO_TAP>;
            // (h)ttp://
            bindings = <&macro_release &kp RCTRL>, <&macro_tap &kp T &kp T &kp P &kp COLON &kp FSLH &kp FSLH>;
        };
        // 'I'
        amgn_if: amgn_if {
            compatible = "zmk,behavior-macro";
            #binding-cells = <0>;
            wait-ms = <U_ANTMORPH_MACRO_WAIT>;
            tap-ms = <U_ANTMORPH_MACRO_TAP>;
            // (i)f 
            bindings = <&macro_tap &kp F &kp SPACE>;
        };
        amgn_if1: amgn_if1 {
            compatible = "zmk,behavior-macro";
            #binding-cells = <0>;
            wait-ms = <U_ANTMORPH_MACRO_WAIT>;
            tap-ms = <U_ANTMORPH_MACRO_TAP>;
            // (i)f [ 
            bindings = <&macro_release &kp RCTRL>, <&macro_tap &kp F &kp SPACE &kp LBKT &kp SPACE>;
        };
        // 'J'
        amgn_journalctl: amgn_journalctl {
            compatible = "zmk,behavior-macro";
            #binding-cells = <0>;
            wait-ms = <U_ANTMORPH_MACRO_WAIT>;
            tap-ms = <U_ANTMORPH_MACRO_TAP>;
            // (j)ournalctl 
            bindings = <&macro_tap &kp O &kp U &kp R &kp N &kp A &kp L &kp C &kp T &kp L &kp SPACE>;
        };
        // 'L'
        amgn_lsof: amgn_lsof {
            compatible = "zmk,behavior-macro";
            #binding-cells = <0>;
            wait-ms = <U_ANTMORPH_MACRO_WAIT>;
            tap-ms = <U_ANTMORPH_MACRO_TAP>;
            // (l)sof 
            bindings = <&macro_tap &kp S &kp O &kp F &kp SPACE>;
        };
        // 'M'
        amgn_meaning: amgn_meaning {
            compatible = "zmk,behavior-macro";
            #binding-cells = <0>;
            wait-ms = <U_ANTMORPH_MACRO_WAIT>;
            tap-ms = <U_ANTMORPH_MACRO_TAP>;
            // (m)eaning
            bindings = <&macro_tap &kp E &kp A &kp N &kp I &kp N &kp G>;
        };
        amgn_mount: amgn_mount {
            compatible = "zmk,behavior-macro";
            #binding-cells = <0>;
            wait-ms = <U_ANTMORPH_MACRO_WAIT>;
            tap-ms = <U_ANTMORPH_MACRO_TAP>;
            // (m)ount 
            bindings = <&macro_tap &kp O &kp U &kp N &kp T &kp SPACE>;
        };
        // 'N'
        amgn_netcat: amgn_netcat {
            compatible = "zmk,behavior-macro";
            #binding-cells = <0>;
            wait-ms = <U_ANTMORPH_MACRO_WAIT>;
            tap-ms = <U_ANTMORPH_MACRO_TAP>;
            // (n)etcat 
            bindings = <&macro_tap &kp E &kp T &kp C &kp A &kp T &kp SPACE>;
        };
        amgn_nmap: amgn_nmap {
            compatible = "zmk,behavior-macro";
            #binding-cells = <0>;
            wait-ms = <U_ANTMORPH_MACRO_WAIT>;
            tap-ms = <U_ANTMORPH_MACRO_TAP>;
            // (n)map 
            bindings = <&macro_tap &kp M &kp A &kp P &kp SPACE>;
        };
        amgn_nslookup: amgn_nslookup {
            compatible = "zmk,behavior-macro";
            #binding-cells = <0>;
            wait-ms = <U_ANTMORPH_MACRO_WAIT>;
            tap-ms = <U_ANTMORPH_MACRO_TAP>;
            // (n)slookup 
            bindings = <&macro_tap &kp S &kp L &kp O &kp O &kp K &kp U &kp P &kp SPACE>;
        };
        amgn_nmcli: amgn_nmcli {
            compatible = "zmk,behavior-macro";
            #binding-cells = <0>;
            wait-ms = <U_ANTMORPH_MACRO_WAIT>;
            tap-ms = <U_ANTMORPH_MACRO_TAP>;
            // (n)mcli 
            bindings = <&macro_tap &kp M &kp C &kp L &kp I &kp SPACE>;
        };
        amgn_netstat: amgn_netstat {
            compatible = "zmk,behavior-macro";
            #binding-cells = <0>;
            wait-ms = <U_ANTMORPH_MACRO_WAIT>;
            tap-ms = <U_ANTMORPH_MACRO_TAP>;
            // (n)etstat 
            bindings = <&macro_tap &kp E &kp T &kp S &kp T &kp A &kp T &kp SPACE>;
        };
        // 'P'
        amgn_ping: amgn_ping {
            compatible = "zmk,behavior-macro";
            #binding-cells = <0>;
            wait-ms = <U_ANTMORPH_MACRO_WAIT>;
            tap-ms = <U_ANTMORPH_MACRO_TAP>;
            // (p)ing 
            bindings = <&macro_tap &kp I &kp N &kp G &kp SPACE>;
        };
        amgn_proostas: amgn_proostas {
            compatible = "zmk,behavior-macro";
            #binding-cells = <0>;
            wait-ms = <U_ANTMORPH_MACRO_WAIT>;
            tap-ms = <U_ANTMORPH_MACRO_TAP>;
            // (p)roostas
            bindings = <&macro_tap &kp R &kp O &kp O &kp S &kp T &kp A &kp S>;
        };
        amgn_pronunciation: amgn_pronunciation {
            compatible = "zmk,behavior-macro";
            #binding-cells = <0>;
            wait-ms = <U_ANTMORPH_MACRO_WAIT>;
            tap-ms = <U_ANTMORPH_MACRO_TAP>;
            // (p)ronunciation
            bindings = <&macro_release &kp LCTRL>, <&macro_tap &kp R &kp O &kp N &kp U &kp N &kp C &kp I &kp A &kp T &kp I &kp O &kp N>;
        };
        // 'R'
        amgn_resolvectl: amgn_resolvectl {
            compatible = "zmk,behavior-macro";
            #binding-cells = <0>;
            wait-ms = <U_ANTMORPH_MACRO_WAIT>;
            tap-ms = <U_ANTMORPH_MACRO_TAP>;
            // (r)esolvectl 
            bindings = <&macro_tap &kp E &kp S &kp O &kp L &kp V &kp E &kp C &kp T &kp L &kp SPACE>;
        };
        // 'S'
        amgn_sysctl: amgn_sysctl {
            compatible = "zmk,behavior-macro";
            #binding-cells = <0>;
            wait-ms = <U_ANTMORPH_MACRO_WAIT>;
            tap-ms = <U_ANTMORPH_MACRO_TAP>;
            // (s)ysctl 
            bindings = <&macro_tap &kp Y &kp S &kp C &kp T &kp L &kp SPACE>;
        };
        amgn_sudo: amgn_sudo {
            compatible = "zmk,behavior-macro";
            #binding-cells = <0>;
            wait-ms = <U_ANTMORPH_MACRO_WAIT>;
            tap-ms = <U_ANTMORPH_MACRO_TAP>;
            // (s)udo 
            bindings = <&macro_tap &kp U &kp D &kp O &kp SPACE>;
        };
        amgn_systemctl: amgn_systemctl {
            compatible = "zmk,behavior-macro";
            #binding-cells = <0>;
            wait-ms = <U_ANTMORPH_MACRO_WAIT>;
            tap-ms = <U_ANTMORPH_MACRO_TAP>;
            // (s)ystemctl 
            bindings = <&macro_tap &kp Y &kp S &kp T &kp E &kp M &kp C &kp T &kp L &kp SPACE>;
        };
        // 'T'
        amgn_trace: amgn_trace {
            compatible = "zmk,behavior-macro";
            #binding-cells = <0>;
            wait-ms = <U_ANTMORPH_MACRO_WAIT>;
            tap-ms = <U_ANTMORPH_MACRO_TAP>;
            // (t)race 
            bindings = <&macro_tap &kp R &kp A &kp C &kp E &kp SPACE>;
        };
        amgn_tmux: amgn_tmux {
            compatible = "zmk,behavior-macro";
            #binding-cells = <0>;
            wait-ms = <U_ANTMORPH_MACRO_WAIT>;
            tap-ms = <U_ANTMORPH_MACRO_TAP>;
            // (t)mux 
            bindings = <&macro_tap &kp M &kp U &kp X &kp SPACE>;
        };
        // 'V'
        amgn_vim: amgn_vim {
            compatible = "zmk,behavior-macro";
            #binding-cells = <0>;
            wait-ms = <U_ANTMORPH_MACRO_WAIT>;
            tap-ms = <U_ANTMORPH_MACRO_TAP>;
            // (v)im 
            bindings = <&macro_tap &kp I &kp M &kp SPACE>;
        };
        // 'W'
        amgn_while: amgn_while {
            compatible = "zmk,behavior-macro";
            #binding-cells = <0>;
            wait-ms = <U_ANTMORPH_MACRO_WAIT>;
            tap-ms = <U_ANTMORPH_MACRO_TAP>;
            // (w)hile 
            bindings = <&macro_tap &kp H &kp I &kp L &kp E &kp SPACE>;
        };
        // '1'
        amgn_12: amgn_12 {
            compatible = "zmk,behavior-macro";
            #binding-cells = <0>;
            wait-ms = <U_ANTMORPH_MACRO_WAIT>;
            tap-ms = <U_ANTMORPH_MACRO_TAP>;
            // (1)>&2
            bindings = <&macro_tap &kp GT &kp AMPS &kp N2>;
        };
        amgn_monday: amgn_monday {
            compatible = "zmk,behavior-macro";
            #binding-cells = <0>;
            wait-ms = <U_ANTMORPH_MACRO_WAIT>;
            tap-ms = <U_ANTMORPH_MACRO_TAP>;
            // [1]Monday
            bindings = <&macro_tap &kp BSPC &kp LS(M) &kp O &kp N &kp D &kp A &kp Y>;
        };
        // '2'
        amgn_21: amgn_21 {
            compatible = "zmk,behavior-macro";
            #binding-cells = <0>;
            wait-ms = <U_ANTMORPH_MACRO_WAIT>;
            tap-ms = <U_ANTMORPH_MACRO_TAP>;
            // (2)>&1
            bindings = <&macro_tap &kp GT &kp AMPS &kp N1>;
        };
        amgn_tuesday: amgn_tuesday {
            compatible = "zmk,behavior-macro";
            #binding-cells = <0>;
            wait-ms = <U_ANTMORPH_MACRO_WAIT>;
            tap-ms = <U_ANTMORPH_MACRO_TAP>;
            // [2]Tuesday
            bindings = <&macro_tap &kp BSPC &kp LS(T) &kp U &kp E &kp S &kp D &kp A &kp Y>;
        };
        // '3'
        amgn_wednesday: amgn_wednesday {
            compatible = "zmk,behavior-macro";
            #binding-cells = <0>;
            wait-ms = <U_ANTMORPH_MACRO_WAIT>;
            tap-ms = <U_ANTMORPH_MACRO_TAP>;
            // [3]Wednesday
            bindings = <&macro_tap &kp BSPC &kp LS(W) &kp E &kp D &kp N &kp E &kp S &kp D &kp A &kp Y>;
        };
        // '4'
        amgn_thursday: amgn_thursday {
            compatible = "zmk,behavior-macro";
            #binding-cells = <0>;
            wait-ms = <U_ANTMORPH_MACRO_WAIT>;
            tap-ms = <U_ANTMORPH_MACRO_TAP>;
            // [4]Thursday
            bindings = <&macro_tap &kp BSPC &kp LS(T) &kp H &kp U &kp R &kp S &kp D &kp A &kp Y>;
        };
        // '5'
        amgn_friday: amgn_friday {
            compatible = "zmk,behavior-macro";
            #binding-cells = <0>;
            wait-ms = <U_ANTMORPH_MACRO_WAIT>;
            tap-ms = <U_ANTMORPH_MACRO_TAP>;
            // [5]Friday
            bindings = <&macro_tap &kp BSPC &kp LS(F) &kp R &kp I &kp D &kp A &kp Y>;
        };
        // '6'
        amgn_saturday: amgn_saturday {
            compatible = "zmk,behavior-macro";
            #binding-cells = <0>;
            wait-ms = <U_ANTMORPH_MACRO_WAIT>;
            tap-ms = <U_ANTMORPH_MACRO_TAP>;
            // [6]Saturday
            bindings = <&macro_tap &kp BSPC &kp LS(S) &kp A &kp T &kp U &kp R &kp D &kp A &kp Y>;
        };
        // '7'
        amgn_sunday: amgn_sunday {
            compatible = "zmk,behavior-macro";
            #binding-cells = <0>;
            wait-ms = <U_ANTMORPH_MACRO_WAIT>;
            tap-ms = <U_ANTMORPH_MACRO_TAP>;
            // [7]Sunday
            bindings = <&macro_tap &kp BSPC &kp LS(S) &kp U &kp N &kp D &kp A &kp Y>;
        };
        // '.'
        amgn_html: amgn_html {
            compatible = "zmk,behavior-macro";
            #binding-cells = <0>;
            wait-ms = <U_ANTMORPH_MACRO_WAIT>;
            tap-ms = <U_ANTMORPH_MACRO_TAP>;
            // (.)html
            bindings = <&macro_tap &kp H &kp T &kp M &kp L>;
        };
        // '@'
        amgn_prokofyevme: amgn_prokofyevme {
            compatible = "zmk,behavior-macro";
            #binding-cells = <0>;
            wait-ms = <U_ANTMORPH_MACRO_WAIT>;
            tap-ms = <U_ANTMORPH_MACRO_TAP>;
            // (@)prokofyev.me
            bindings = <&macro_tap &kp P &kp R &kp O &kp K &kp O &kp F &kp Y &kp E &kp V &kp DOT &kp M &kp E>;
        };
        amgn_yandexru: amgn_yandexru {
            compatible = "zmk,behavior-macro";
            #binding-cells = <0>;
            wait-ms = <U_ANTMORPH_MACRO_WAIT>;
            tap-ms = <U_ANTMORPH_MACRO_TAP>;
            // (@)yandex.ru
            bindings = <&macro_tap &kp Y &kp A &kp N &kp D &kp E &kp X &kp DOT &kp R &kp U>;
        };
        amgn_gmailcom: amgn_gmailcom {
            compatible = "zmk,behavior-macro";
            #binding-cells = <0>;
            wait-ms = <U_ANTMORPH_MACRO_WAIT>;
            tap-ms = <U_ANTMORPH_MACRO_TAP>;
            // (@)gmail.com
            bindings = <&macro_tap &kp G &kp M &kp A &kp I &kp L &kp DOT &kp C &kp O &kp M>;
        };
        // '#'
        amgn_binsh: amgn_binsh {
            compatible = "zmk,behavior-macro";
            #binding-cells = <0>;
            wait-ms = <U_ANTMORPH_MACRO_WAIT>;
            tap-ms = <U_ANTMORPH_MACRO_TAP>;
            // (#)!/bin/sh
            bindings = <&macro_tap &kp EXCL &kp FSLH &kp B &kp I &kp N &kp FSLH &kp S &kp H>;
        };
        amgn_usrbinpython: amgn_usrbinpython {
            compatible = "zmk,behavior-macro";
            #binding-cells = <0>;
            wait-ms = <U_ANTMORPH_MACRO_WAIT>;
            tap-ms = <U_ANTMORPH_MACRO_TAP>;
            // (#)!/usr/bin/python
            bindings = <&macro_release &kp LCTRL>, <&macro_tap &kp EXCL &kp FSLH &kp U &kp S &kp R &kp FSLH &kp B &kp I &kp N &kp FSLH &kp P &kp Y &kp T &kp H &kp O &kp N>;
        };
        amgn_usrbinenv: amgn_usrbinenv {
            compatible = "zmk,behavior-macro";
            #binding-cells = <0>;
            wait-ms = <U_ANTMORPH_MACRO_WAIT>;
            tap-ms = <U_ANTMORPH_MACRO_TAP>;
            // (#)!/usr/bin/env 
            bindings = <&macro_release &kp LALT>, <&macro_tap &kp LALT>, <&macro_tap &kp EXCL &kp FSLH &kp U &kp S &kp R &kp FSLH &kp B &kp I &kp N &kp FSLH &kp E &kp N &kp V &kp SPACE>;
        };
        // '['
        amgn__e: amgn__e {
            compatible = "zmk,behavior-macro";
            #binding-cells = <0>;
            wait-ms = <U_ANTMORPH_MACRO_WAIT>;
            tap-ms = <U_ANTMORPH_MACRO_TAP>;
            // ([) -e 
            bindings = <&macro_tap &kp SPACE &kp MINUS &kp E &kp SPACE>;
        };
        amgn__: amgn__ {
            compatible = "zmk,behavior-macro";
            #binding-cells = <0>;
            wait-ms = <U_ANTMORPH_MACRO_WAIT>;
            tap-ms = <U_ANTMORPH_MACRO_TAP>;
            // ([) -
            bindings = <&macro_tap &kp SPACE &kp MINUS>;
        };
        amgn__x: amgn__x {
            compatible = "zmk,behavior-macro";
            #binding-cells = <0>;
            wait-ms = <U_ANTMORPH_MACRO_WAIT>;
            tap-ms = <U_ANTMORPH_MACRO_TAP>;
            // ([) -x 
            bindings = <&macro_tap &kp SPACE &kp MINUS &kp X &kp SPACE>;
        };
        amgn__z: amgn__z {
            compatible = "zmk,behavior-macro";
            #binding-cells = <0>;
            wait-ms = <U_ANTMORPH_MACRO_WAIT>;
            tap-ms = <U_ANTMORPH_MACRO_TAP>;
            // ([) -z 
            bindings = <&macro_tap &kp SPACE &kp MINUS &kp Z &kp SPACE>;
        };
        amgn__n: amgn__n {
            compatible = "zmk,behavior-macro";
            #binding-cells = <0>;
            wait-ms = <U_ANTMORPH_MACRO_WAIT>;
            tap-ms = <U_ANTMORPH_MACRO_TAP>;
            // ([) -n 
            bindings = <&macro_release &kp RCTRL>, <&macro_tap &kp SPACE &kp MINUS &kp N &kp SPACE>;
        };
        // ';'
        amgn_do: amgn_do {
            compatible = "zmk,behavior-macro";
            #binding-cells = <0>;
            wait-ms = <U_ANTMORPH_MACRO_WAIT>;
            tap-ms = <U_ANTMORPH_MACRO_TAP>;
            // (;) do⏎
            bindings = <&macro_tap &kp SPACE &kp D &kp O &kp RET>;
        };
        amgn_then: amgn_then {
            compatible = "zmk,behavior-macro";
            #binding-cells = <0>;
            wait-ms = <U_ANTMORPH_MACRO_WAIT>;
            tap-ms = <U_ANTMORPH_MACRO_TAP>;
            // (;) then⏎
            bindings = <&macro_tap &kp SPACE &kp T &kp H &kp E &kp N &kp RET>;
        };
        // ' '
        amgn_general_v29: amgn_general_v29 {
            compatible = "zmk,behavior-macro";
            #binding-cells = <0>;
            wait-ms = <U_ANTMORPH_MACRO_WAIT>;
            tap-ms = <U_ANTMORPH_MACRO_TAP>;
            // [ ]General v2.9
            bindings = <&macro_release &kp LCTRL>, <&macro_tap &kp BSPC &kp LS(G) &kp E &kp N &kp E &kp R &kp A &kp L &kp SPACE &kp V &kp N2 &kp DOT &kp N9>;
        };
        amgn_m: amgn_m {
            compatible = "zmk,behavior-macro";
            #binding-cells = <0>;
            wait-ms = <U_ANTMORPH_MACRO_WAIT>;
            tap-ms = <U_ANTMORPH_MACRO_TAP>;
            // ( )== 
            bindings = <&macro_release &kp RCTRL>, <&macro_tap &kp EQUAL &kp EQUAL &kp SPACE>;
        };
        amgn_m1: amgn_m1 {
            compatible = "zmk,behavior-macro";
            #binding-cells = <0>;
            wait-ms = <U_ANTMORPH_MACRO_WAIT>;
            tap-ms = <U_ANTMORPH_MACRO_TAP>;
            // ( )!= 
            bindings = <&macro_release &kp RALT>, <&macro_tap &kp RALT>, <&macro_tap &kp EXCL &kp EQUAL &kp SPACE>;
        };
    };
};
